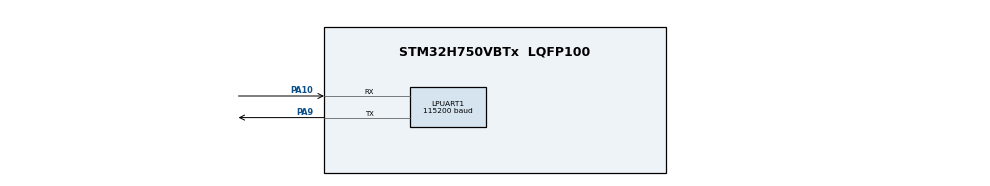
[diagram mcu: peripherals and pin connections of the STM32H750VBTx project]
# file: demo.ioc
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Bdma.LPUART1_RX.0.Direction=DMA_PERIPH_TO_MEMORY
Bdma.LPUART1_RX.0.EventEnable=DISABLE
Bdma.LPUART1_RX.0.Instance=BDMA_Channel0
Bdma.LPUART1_RX.0.MemDataAlignment=DMA_MDATAALIGN_BYTE
Bdma.LPUART1_RX.0.MemInc=DMA_MINC_ENABLE
Bdma.LPUART1_RX.0.Mode=DMA_NORMAL
Bdma.LPUART1_RX.0.PeriphDataAlignment=DMA_PDATAALIGN_BYTE
Bdma.LPUART1_RX.0.PeriphInc=DMA_PINC_DISABLE
Bdma.LPUART1_RX.0.Polarity=HAL_DMAMUX_REQ_GEN_RISING
Bdma.LPUART1_RX.0.Priority=DMA_PRIORITY_LOW
Bdma.LPUART1_RX.0.RequestNumber=1
Bdma.LPUART1_RX.0.SignalID=NONE
Bdma.LPUART1_RX.0.SyncEnable=DISABLE
Bdma.LPUART1_RX.0.SyncPolarity=HAL_DMAMUX_SYNC_NO_EVENT
Bdma.LPUART1_RX.0.SyncRequestNumber=1
Bdma.LPUART1_RX.0.SyncSignalID=NONE
Bdma.LPUART1_TX.1.Direction=DMA_MEMORY_TO_PERIPH
Bdma.LPUART1_TX.1.EventEnable=DISABLE
Bdma.LPUART1_TX.1.Instance=BDMA_Channel1
Bdma.LPUART1_TX.1.MemDataAlignment=DMA_MDATAALIGN_BYTE
Bdma.LPUART1_TX.1.MemInc=DMA_MINC_ENABLE
Bdma.LPUART1_TX.1.Mode=DMA_NORMAL
Bdma.LPUART1_TX.1.PeriphDataAlignment=DMA_PDATAALIGN_BYTE
Bdma.LPUART1_TX.1.PeriphInc=DMA_PINC_DISABLE
Bdma.LPUART1_TX.1.Polarity=HAL_DMAMUX_REQ_GEN_RISING
Bdma.LPUART1_TX.1.Priority=DMA_PRIORITY_LOW
Bdma.LPUART1_TX.1.RequestNumber=1
Bdma.LPUART1_TX.1.SignalID=NONE
Bdma.LPUART1_TX.1.SyncEnable=DISABLE
Bdma.LPUART1_TX.1.SyncPolarity=HAL_DMAMUX_SYNC_NO_EVENT
Bdma.LPUART1_TX.1.SyncRequestNumber=1
Bdma.LPUART1_TX.1.SyncSignalID=NONE
Bdma.Request0=LPUART1_RX
Bdma.Request1=LPUART1_TX
Bdma.RequestsNb=2
CORTEX_M7.AccessPermission-Cortex_Memory_Protection_Unit_Region2_Settings=MPU_REGION_FULL_ACCESS
CORTEX_M7.BaseAddress-Cortex_Memory_Protection_Unit_Region2_Settings=0x24000000
CORTEX_M7.Enable-Cortex_Memory_Protection_Unit_Region0_Settings=__NULL
CORTEX_M7.Enable-Cortex_Memory_Protection_Unit_Region2_Settings=MPU_REGION_ENABLE
CORTEX_M7.IsCacheable-Cortex_Memory_Protection_Unit_Region2_Settings=MPU_ACCESS_CACHEABLE
CORTEX_M7.IsShareable-Cortex_Memory_Protection_Unit_Region2_Settings=MPU_ACCESS_SHAREABLE
CORTEX_M7.MPU_Control=__NULL
CORTEX_M7.Size-Cortex_Memory_Protection_Unit_Region2_Settings=MPU_REGION_SIZE_512KB
FREERTOS.BinarySemaphores01=usarrtBinary,Dynamic,NULL
FREERTOS.Tasks01=defaultTask,0,128,StartDefaultTask,Default,NULL,Dynamic,NULL,NULL;myTask02,-2,128,StartTask02,Default,NULL,Dynamic,NULL,NULL;myTask03,-2,128,StartTask03,Default,NULL,Dynamic,NULL,NULL
LPUART1.BaudRate=115200
LPUART1.FIFOMode=UART_FIFOMODE_DISABLE
Mcu.Family=STM32H7
Mcu.Name=STM32H750VBTx
Mcu.Package=LQFP100
NVIC.BDMA_Channel0_IRQn=true\:7\:0\:true\:false\:true\:false\:true\:true\:true
NVIC.BDMA_Channel1_IRQn=true\:7\:0\:true\:false\:true\:false\:false\:true\:true
NVIC.LPUART1_IRQn=true\:7\:0\:true\:false\:true\:false\:true\:true\:true
NVIC.PriorityGroup=NVIC_PRIORITYGROUP_4
NVIC.TIM17_IRQn=true\:4\:0\:true\:false\:true\:false\:false\:true\:true
NVIC.TimeBase=TIM17_IRQn
NVIC.TimeBaseIP=TIM17
PA10.Mode=Asynchronous
PA10.Signal=LPUART1_RX
PA9.Mode=Asynchronous
PA9.Signal=LPUART1_TX
PC14-OSC32_IN\ (OSC32_IN).Mode=LSE-External-Oscillator
PC14-OSC32_IN\ (OSC32_IN).Signal=RCC_OSC32_IN
PC15-OSC32_OUT\ (OSC32_OUT).Mode=LSE-External-Oscillator
PC15-OSC32_OUT\ (OSC32_OUT).Signal=RCC_OSC32_OUT
PH0-OSC_IN\ (PH0).Mode=HSE-External-Oscillator
PH0-OSC_IN\ (PH0).Signal=RCC_OSC_IN
PH1-OSC_OUT\ (PH1).Mode=HSE-External-Oscillator
PH1-OSC_OUT\ (PH1).Signal=RCC_OSC_OUT
ProjectManager.HeapSize=0x200
ProjectManager.StackSize=0x400
ProjectManager.TargetToolchain=MDK-ARM V5.32
RCC.ADCFreq_Value=129000000
RCC.APB1Freq_Value=64000000
RCC.APB2Freq_Value=32000000
RCC.APB3Freq_Value=32000000
RCC.APB4Freq_Value=64000000
RCC.CortexFreq_Value=64000000
RCC.D1PPRE=RCC_APB3_DIV2
RCC.D2PPRE2=RCC_APB2_DIV2
RCC.HCLKFreq_Value=64000000
RCC.SYSCLKFreq_VALUE=64000000
RCC.USBFreq_Value=129000000
TIM1.Period=500-1
TIM1.Prescaler=64000-1
VP_FREERTOS_VS_CMSIS_V1.Mode=CMSIS_V1
VP_SYS_VS_tim17.Mode=TIM17
VP_TIM1_VS_ClockSourceINT.Mode=Internal
board=custom

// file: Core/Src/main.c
/* USER CODE BEGIN Header */
/**
  ******************************************************************************
  * @file           : main.c
  * @brief          : Main program body
  ******************************************************************************
  * @attention
  *
  * Copyright (c) 2023 STMicroelectronics.
  * All rights reserved.
  *
  * This software is licensed under terms that can be found in the LICENSE file
  * in the root directory of this software component.
  * If no LICENSE file comes with this software, it is provided AS-IS.
  *
  ******************************************************************************
  */
/* USER CODE END Header */
#include "main.h"
#include "cmsis_os.h"
#include "bdma.h"
#include "usart.h"
#include "tim.h"
#include "gpio.h"

/* USER CODE BEGIN Includes */
#include <stdio.h>
#include <string.h>
#include "stm32h750xx.h"
/* USER CODE END Includes */

/* USER CODE BEGIN PV */
extern uint8_t rx_buffer[200];

/* USER CODE END PV */

void SystemClock_Config(void);
void MX_FREERTOS_Init(void);

int main(void)
{

  /* MCU Configuration--------------------------------------------------------*/

  /* Reset of all peripherals, Initializes the Flash interface and the Systick. */
  HAL_Init();

  /* Configure the system clock */
  SystemClock_Config();

  /* Initialize all configured peripherals */
  MX_GPIO_Init();
  MX_BDMA_Init();
  MX_LPUART1_UART_Init();
  MX_TIM1_Init();
  /* USER CODE BEGIN 2 */
  memset(rx_buffer, 0, sizeof(rx_buffer));
	__HAL_UART_ENABLE_IT(&hlpuart1, UART_IT_IDLE);

	HAL_UART_Receive_DMA(&hlpuart1,rx_buffer,sizeof(rx_buffer));

	printf("work\r\n");
  /* USER CODE END 2 */

  /* Call init function for freertos objects (in freertos.c) */
  MX_FREERTOS_Init();

  /* Start scheduler */
  osKernelStart();

  /* We should never get here as control is now taken by the scheduler */
  /* Infinite loop */
  while (1)
  {

  }
}

void SystemClock_Config(void)
{
  RCC_OscInitTypeDef RCC_OscInitStruct = {0};
  RCC_ClkInitTypeDef RCC_ClkInitStruct = {0};

  /** Supply configuration update enable
  */
  HAL_PWREx_ConfigSupply(PWR_LDO_SUPPLY);

  /** Configure the main internal regulator output voltage
  */
  __HAL_PWR_VOLTAGESCALING_CONFIG(PWR_REGULATOR_VOLTAGE_SCALE3);

  while(!__HAL_PWR_GET_FLAG(PWR_FLAG_VOSRDY)) {}

  /** Initializes the RCC Oscillators according to the specified parameters
  * in the RCC_OscInitTypeDef structure.
  */
  RCC_OscInitStruct.OscillatorType = RCC_OSCILLATORTYPE_HSI;
  RCC_OscInitStruct.HSIState = RCC_HSI_DIV1;
  RCC_OscInitStruct.HSICalibrationValue = RCC_HSICALIBRATION_DEFAULT;
  RCC_OscInitStruct.PLL.PLLState = RCC_PLL_NONE;
  if (HAL_RCC_OscConfig(&RCC_OscInitStruct) != HAL_OK)
  {
    Error_Handler();
  }

  /** Initializes the CPU, AHB and APB buses clocks
  */
  RCC_ClkInitStruct.ClockType = RCC_CLOCKTYPE_HCLK|RCC_CLOCKTYPE_SYSCLK
                              |RCC_CLOCKTYPE_PCLK1|RCC_CLOCKTYPE_PCLK2
                              |RCC_CLOCKTYPE_D3PCLK1|RCC_CLOCKTYPE_D1PCLK1;
  RCC_ClkInitStruct.SYSCLKSource = RCC_SYSCLKSOURCE_HSI;
  RCC_ClkInitStruct.SYSCLKDivider = RCC_SYSCLK_DIV1;
  RCC_ClkInitStruct.AHBCLKDivider = RCC_HCLK_DIV1;
  RCC_ClkInitStruct.APB3CLKDivider = RCC_APB3_DIV2;
  RCC_ClkInitStruct.APB1CLKDivider = RCC_APB1_DIV1;
  RCC_ClkInitStruct.APB2CLKDivider = RCC_APB2_DIV2;
  RCC_ClkInitStruct.APB4CLKDivider = RCC_APB4_DIV1;

  if (HAL_RCC_ClockConfig(&RCC_ClkInitStruct, FLASH_LATENCY_1) != HAL_OK)
  {
    Error_Handler();
  }
}

void HAL_TIM_PeriodElapsedCallback(TIM_HandleTypeDef *htim)
{
  if (htim->Instance == TIM17) {
    HAL_IncTick();
  }
}

void Error_Handler(void)
{
  __disable_irq();
  while (1)
  {
  }
}

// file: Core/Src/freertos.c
/* USER CODE BEGIN Header */
/**
  ******************************************************************************
  * File Name          : freertos.c
  * Description        : Code for freertos applications
  ******************************************************************************
  * @attention
  *
  * Copyright (c) 2023 STMicroelectronics.
  * All rights reserved.
  *
  * This software is licensed under terms that can be found in the LICENSE file
  * in the root directory of this software component.
  * If no LICENSE file comes with this software, it is provided AS-IS.
  *
  ******************************************************************************
  */
/* USER CODE END Header */

#include "FreeRTOS.h"
#include "task.h"
#include "main.h"
#include "cmsis_os.h"

/* USER CODE BEGIN Includes */
#include <stdio.h>
#include <string.h>
/* USER CODE END Includes */

/* USER CODE BEGIN PTD */
extern uint8_t rx_buffer[200];
/* USER CODE END PTD */

osThreadId defaultTaskHandle;
osThreadId myTask02Handle;
osThreadId myTask03Handle;
osSemaphoreId usarrtBinaryHandle;

void StartDefaultTask(void const * argument);
void StartTask02(void const * argument);
void StartTask03(void const * argument);

void MX_FREERTOS_Init(void); /* (MISRA C 2004 rule 8.1) */

/* GetIdleTaskMemory prototype (linked to static allocation support) */
void vApplicationGetIdleTaskMemory( StaticTask_t **ppxIdleTaskTCBBuffer, StackType_t **ppxIdleTaskStackBuffer, uint32_t *pulIdleTaskStackSize );

/* USER CODE BEGIN GET_IDLE_TASK_MEMORY */
static StaticTask_t xIdleTaskTCBBuffer;
static StackType_t xIdleStack[configMINIMAL_STACK_SIZE];

void vApplicationGetIdleTaskMemory( StaticTask_t **ppxIdleTaskTCBBuffer, StackType_t **ppxIdleTaskStackBuffer, uint32_t *pulIdleTaskStackSize )
{
  *ppxIdleTaskTCBBuffer = &xIdleTaskTCBBuffer;
  *ppxIdleTaskStackBuffer = &xIdleStack[0];
  *pulIdleTaskStackSize = configMINIMAL_STACK_SIZE;
  /* place for user code */
}
/* USER CODE END GET_IDLE_TASK_MEMORY */

void MX_FREERTOS_Init(void) {

  /* Create the semaphores(s) */
  /* definition and creation of usarrtBinary */
  osSemaphoreDef(usarrtBinary);
  usarrtBinaryHandle = osSemaphoreCreate(osSemaphore(usarrtBinary), 1);

  /* Create the thread(s) */
  /* definition and creation of defaultTask */
  osThreadDef(defaultTask, StartDefaultTask, osPriorityNormal, 0, 128);
  defaultTaskHandle = osThreadCreate(osThread(defaultTask), NULL);

  /* definition and creation of myTask02 */
  osThreadDef(myTask02, StartTask02, osPriorityLow, 0, 128);
  myTask02Handle = osThreadCreate(osThread(myTask02), NULL);

  /* definition and creation of myTask03 */
  osThreadDef(myTask03, StartTask03, osPriorityLow, 0, 128);
  myTask03Handle = osThreadCreate(osThread(myTask03), NULL);

}

void StartDefaultTask(void const * argument)
{
  for(;;)
  {
    osDelay(1);
  }
}

void StartTask02(void const * argument)
{
  /* USER CODE BEGIN StartTask02 */
  BaseType_t err=pdFALSE;
  /* Infinite loop */
  for(;;)
  {
    if(usarrtBinaryHandle!=NULL)
    {
      err=xSemaphoreTake(usarrtBinaryHandle,portMAX_DELAY);//获取信号量
      if(err==pdTRUE) //获取信号量成功
      {
        printf("usart rec data:%s\r\n",rx_buffer);
      }
    }
    osDelay(500);
  }
  /* USER CODE END StartTask02 */
}

void StartTask03(void const * argument)
{
  /* USER CODE BEGIN StartTask03 */
  /* Infinite loop */
  for(;;)
  {
    osDelay(1000);
  }
  /* USER CODE END StartTask03 */
}
